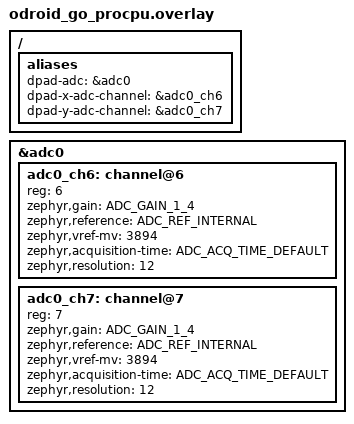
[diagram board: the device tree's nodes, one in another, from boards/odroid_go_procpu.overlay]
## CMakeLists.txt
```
set(BOARD "odroid_go/esp32/procpu")

cmake_minimum_required(VERSION 3.13.1)
find_package(Zephyr REQUIRED HINTS $ENV{ZEPHYR_BASE})

project(app LANGUAGES C)

target_sources(app PRIVATE src/main.c)
```

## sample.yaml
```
# This file is provided so that the application can be compiled using Twister,
# the Zephyr testing tool. In this file, multiple combinations can be specified,
# so that you can easily test all of them locally or in CI.
sample:
  description: Example application
  name: example-application 
common:
  build_only: true
  integration_platforms:
    - odroid_go/esp32/procpu
tests:
  app.default: {}
  app.debug:
    extra_overlay_confs:
      - debug.conf
```

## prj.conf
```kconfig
CONFIG_ODROID_GO_BUTTONS=y

CONFIG_ZBUS=y

CONFIG_GPIO=y
CONFIG_ADC=y
CONFIG_INPUT=y

CONFIG_DISPLAY=y
CONFIG_LVGL=y
CONFIG_LV_Z_MEM_POOL_SIZE=32768
CONFIG_LV_USE_LOG=y
CONFIG_LV_USE_LABEL=y
CONFIG_LV_USE_ARC=y
CONFIG_LV_COLOR_16_SWAP=y
```

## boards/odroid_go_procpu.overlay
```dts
/ {
	aliases {
		dpad-adc = &adc0;
		dpad-x-adc-channel = &adc0_ch6;
		dpad-y-adc-channel = &adc0_ch7;
	};
};

&adc0 {
	status = "okay";
	#address-cells = <1>;
	#size-cells = <0>;

	adc0_ch6: channel@6 {
		reg = <6>;
		zephyr,gain = "ADC_GAIN_1_4";
		zephyr,reference = "ADC_REF_INTERNAL";
		zephyr,vref-mv = <3894>;
		zephyr,acquisition-time = <ADC_ACQ_TIME_DEFAULT>;
		zephyr,resolution = <12>;
	};

	adc0_ch7: channel@7 {
		reg = <7>;
		zephyr,gain = "ADC_GAIN_1_4";
		zephyr,reference = "ADC_REF_INTERNAL";
		zephyr,vref-mv = <3894>;
		zephyr,acquisition-time = <ADC_ACQ_TIME_DEFAULT>;
		zephyr,resolution = <12>;
	};
};
```

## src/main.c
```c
#include <stdint.h>
#include <stdio.h>
#include <zephyr/drivers/display.h>
#include <zephyr/drivers/gpio.h>
#include <zephyr/kernel.h>
#include <zephyr/zbus/zbus.h>

#include "app/drivers/odroid_go_buttons.h"

static const struct gpio_dt_spec led = GPIO_DT_SPEC_GET(DT_ALIAS(led0), gpios);

void button_callback_ui(const struct zbus_channel* channel) {
	if (channel != &button_event_channel) {
		return;
	}
	const struct ButtonEvent* event = zbus_chan_const_msg(channel);
	switch (event->type) {
		case BUTTON_A_PRESSED:
			gpio_pin_set_dt(&led, 1);
			break;
		case BUTTON_A_RELEASED:
			gpio_pin_set_dt(&led, 0);
			break;
		default:
			break;
	}
}

ZBUS_LISTENER_DEFINE(button_observer_ui, button_callback_ui);
ZBUS_CHAN_ADD_OBS(button_event_channel, ZBUS_OBSERVERS(button_observer_ui), 0);

int main(void) {
	if (!gpio_is_ready_dt(&led)) {
		printf("Could not init GPIO\n");
		return 0;
	}

	int pin_config_error = gpio_pin_configure_dt(&led, GPIO_OUTPUT_ACTIVE);
	if (pin_config_error < 0) {
		return 0;
	}
	gpio_pin_set_dt(&led, 0);

	while (1) {
		k_sleep(K_MSEC(50));
	}
	return 0;
}
```
